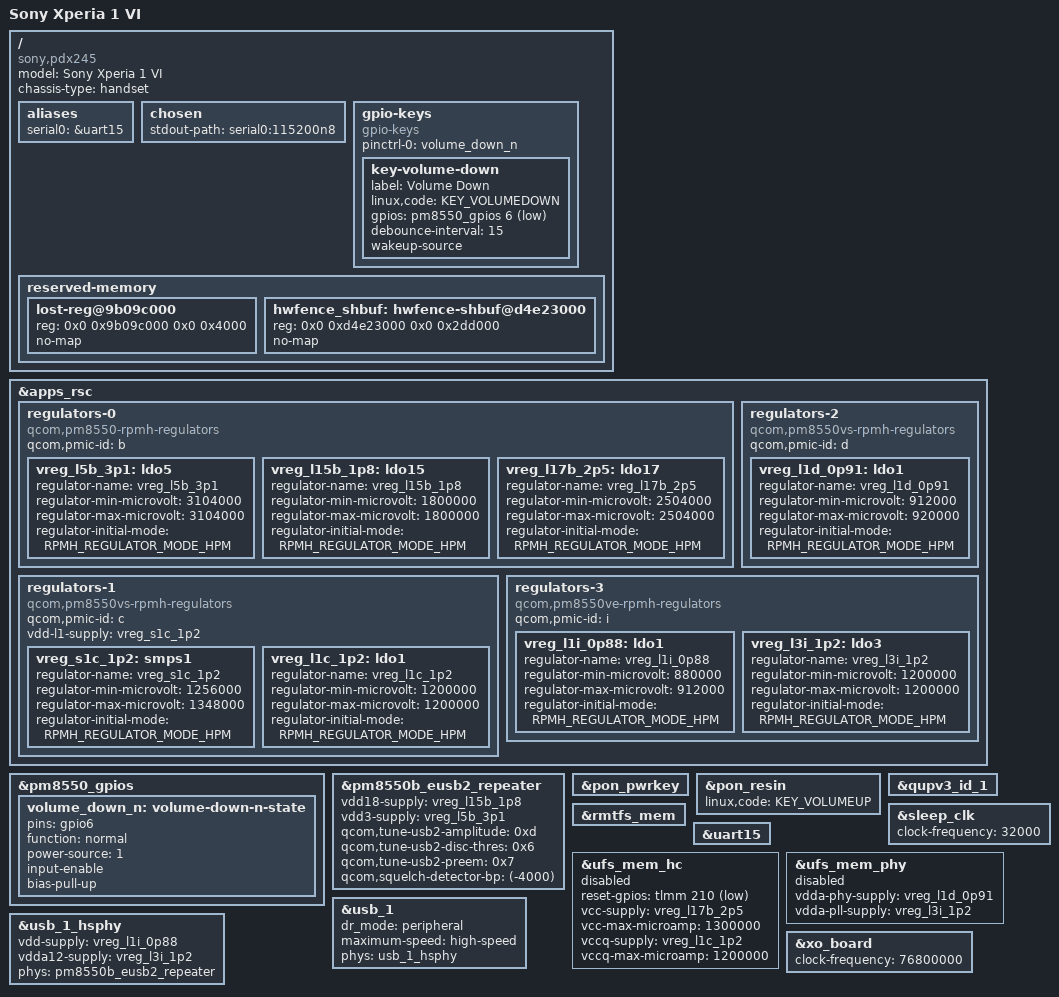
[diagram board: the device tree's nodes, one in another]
// SPDX-License-Identifier: BSD-3-Clause

/dts-v1/;

#include <dt-bindings/input/input.h>
#include <dt-bindings/regulator/qcom,rpmh-regulator.h>
#include "sm8650.dtsi"
#include "pm8550.dtsi"
#include "pm8550b.dtsi"
#include "pmk8550.dtsi"

/delete-node/ &hwfence_shbuf;

/ {
	model = "Sony Xperia 1 VI";
	compatible = "sony,pdx245", "qcom,sm8650";
	chassis-type = "handset";

	aliases {
		serial0 = &uart15;
	};

	chosen {
		stdout-path = "serial0:115200n8";
	};

	gpio-keys {
		compatible = "gpio-keys";

		pinctrl-0 = <&volume_down_n>;
		pinctrl-names = "default";

		key-volume-down {
			label = "Volume Down";
			linux,code = <KEY_VOLUMEDOWN>;
			gpios = <&pm8550_gpios 6 GPIO_ACTIVE_LOW>;
			debounce-interval = <15>;
			wakeup-source;
		};
	};

	reserved-memory {
		lost-reg@9b09c000 {
			reg = <0x0 0x9b09c000 0x0 0x4000>;
			no-map;
		};

		hwfence_shbuf: hwfence-shbuf@d4e23000 {
			reg = <0x0 0xd4e23000 0x0 0x2dd000>;
			no-map;
		};
	};
};

&apps_rsc {
	regulators-0 {
		compatible = "qcom,pm8550-rpmh-regulators";
		qcom,pmic-id = "b";

		vreg_l5b_3p1: ldo5 {
			regulator-name = "vreg_l5b_3p1";
			regulator-min-microvolt = <3104000>;
			regulator-max-microvolt = <3104000>;
			regulator-initial-mode = <RPMH_REGULATOR_MODE_HPM>;
		};

		vreg_l15b_1p8: ldo15 {
			regulator-name = "vreg_l15b_1p8";
			regulator-min-microvolt = <1800000>;
			regulator-max-microvolt = <1800000>;
			regulator-initial-mode = <RPMH_REGULATOR_MODE_HPM>;
		};

		vreg_l17b_2p5: ldo17 {
			regulator-name = "vreg_l17b_2p5";
			regulator-min-microvolt = <2504000>;
			regulator-max-microvolt = <2504000>;
			regulator-initial-mode = <RPMH_REGULATOR_MODE_HPM>;
		};
	};

	regulators-1 {
		compatible = "qcom,pm8550vs-rpmh-regulators";
		qcom,pmic-id = "c";

		vdd-l1-supply = <&vreg_s1c_1p2>;

		vreg_s1c_1p2: smps1 {
			regulator-name = "vreg_s1c_1p2";
			regulator-min-microvolt = <1256000>;
			regulator-max-microvolt = <1348000>;
			regulator-initial-mode = <RPMH_REGULATOR_MODE_HPM>;
		};

		vreg_l1c_1p2: ldo1 {
			regulator-name = "vreg_l1c_1p2";
			regulator-min-microvolt = <1200000>;
			regulator-max-microvolt = <1200000>;
			regulator-initial-mode = <RPMH_REGULATOR_MODE_HPM>;
		};
	};

	regulators-2 {
		compatible = "qcom,pm8550vs-rpmh-regulators";
		qcom,pmic-id = "d";

		vreg_l1d_0p91: ldo1 {
			regulator-name = "vreg_l1d_0p91";
			regulator-min-microvolt = <912000>;
			regulator-max-microvolt = <920000>;
			regulator-initial-mode = <RPMH_REGULATOR_MODE_HPM>;
		};
	};

	regulators-3 {
		compatible = "qcom,pm8550ve-rpmh-regulators";
		qcom,pmic-id = "i";

		vreg_l1i_0p88: ldo1 {
			regulator-name = "vreg_l1i_0p88";
			regulator-min-microvolt = <880000>;
			regulator-max-microvolt = <912000>;
			regulator-initial-mode = <RPMH_REGULATOR_MODE_HPM>;
		};

		vreg_l3i_1p2: ldo3 {
			regulator-name = "vreg_l3i_1p2";
			regulator-min-microvolt = <1200000>;
			regulator-max-microvolt = <1200000>;
			regulator-initial-mode = <RPMH_REGULATOR_MODE_HPM>;
		};
	};
};

&pm8550_gpios {
	volume_down_n: volume-down-n-state {
		pins = "gpio6";
		function = "normal";
		power-source = <1>;
		input-enable;
		bias-pull-up;
	};
};

&pm8550b_eusb2_repeater {
	vdd18-supply = <&vreg_l15b_1p8>;
	vdd3-supply = <&vreg_l5b_3p1>;

	qcom,tune-usb2-amplitude = /bits/ 8 <0xd>;
	qcom,tune-usb2-disc-thres = /bits/ 8 <0x6>;
	qcom,tune-usb2-preem = /bits/ 8 <0x7>;
	qcom,squelch-detector-bp = <(-4000)>;
};

&pon_pwrkey {
	status = "okay";
};

&pon_resin {
	linux,code = <KEY_VOLUMEUP>;
	status = "okay";
};

&qupv3_id_1 {
	status = "okay";
};

/*
 * The downstream DT does not identify a fixed rmtfs allocation. Keep the
 * SoC reservation for now, but do not hand that unverified region to a modem.
 */
&rmtfs_mem {
	/delete-property/ compatible;
	/delete-property/ qcom,client-id;
	/delete-property/ qcom,vmid;
};

&sleep_clk {
	clock-frequency = <32000>;
};

&uart15 {
	status = "okay";
};

/*
 * Describe the evidenced storage topology, but leave it off until the
 * downstream VDD_PX10 vote for ufs_reset_n has a mainline representation.
 */
&ufs_mem_hc {
	reset-gpios = <&tlmm 210 GPIO_ACTIVE_LOW>;

	vcc-supply = <&vreg_l17b_2p5>;
	vcc-max-microamp = <1300000>;
	vccq-supply = <&vreg_l1c_1p2>;
	vccq-max-microamp = <1200000>;

	status = "disabled";
};

&ufs_mem_phy {
	vdda-phy-supply = <&vreg_l1d_0p91>;
	vdda-pll-supply = <&vreg_l3i_1p2>;

	status = "disabled";
};

/*
 * First diagnostic path: USB2 device mode only. Sony's Type-C/CC firmware
 * handoff still needs testing; do not enable the QRD's SS/DP/role-switch path.
 */
&usb_1 {
	dr_mode = "peripheral";
	maximum-speed = "high-speed";
	phys = <&usb_1_hsphy>;
	phy-names = "usb2-phy";

	status = "okay";
};

&usb_1_hsphy {
	vdd-supply = <&vreg_l1i_0p88>;
	vdda12-supply = <&vreg_l3i_1p2>;
	phys = <&pm8550b_eusb2_repeater>;

	status = "okay";
};

&xo_board {
	clock-frequency = <76800000>;
};
